# MSEBIM register map
Registers from a debugger description file.
Registers are 32-bit, access not given, no defined reset value unless marked. A register's access mark holds for its fields unless they carry their own. Addresses are absolute; registers are grouped by the start of their names; lines under a group give offsets from that group; [hi:lo] are bit positions; {n}, {i} and the like mark numbered series; 'fields as' and 'values as' point back to an identical list; <NAME> marks a mode.

## rMSEBIM
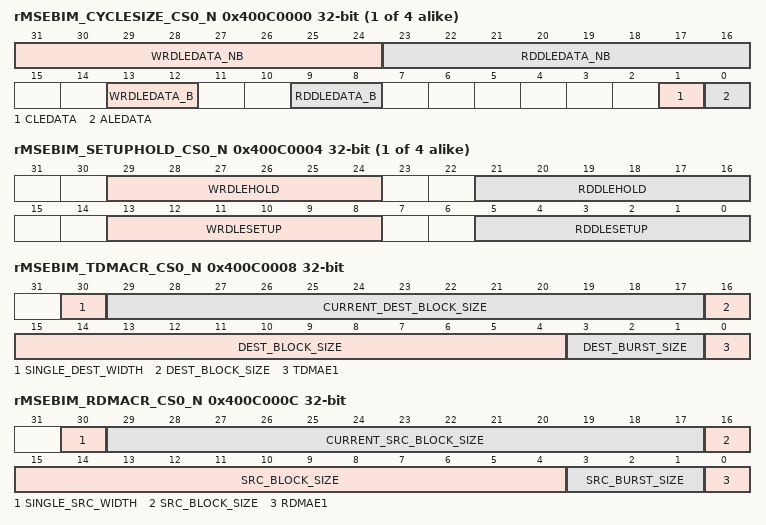
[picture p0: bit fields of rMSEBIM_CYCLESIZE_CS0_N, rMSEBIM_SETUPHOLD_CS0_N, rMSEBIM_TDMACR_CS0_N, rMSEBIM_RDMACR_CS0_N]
{0x400C0000+0x100*i} rMSEBIM_CYCLESIZE_CS{i}_N (i=0..3)
  [31:24] WRDLEDATA_NB, [23:16] RDDLEDATA_NB, [13:12] WRDLEDATA_B, [9:8] RDDLEDATA_B, [1] CLEDATA, [0] ALEDATA
{0x400C0004+0x100*i} rMSEBIM_SETUPHOLD_CS{i}_N (i=0..3)
  [29:24] WRDLEHOLD, [21:16] RDDLEHOLD, [13:8] WRDLESETUP, [5:0] RDDLESETUP
0x400C0008 rMSEBIM_TDMACR_CS0_N
  [30] SINGLE_DEST_WIDTH, [29:17] CURRENT_DEST_BLOCK_SIZE, [16:4] DEST_BLOCK_SIZE, [3:1] DEST_BURST_SIZE, [0] TDMAE1
0x400C000C rMSEBIM_RDMACR_CS0_N
  [30] SINGLE_SRC_WIDTH, [29:17] CURRENT_SRC_BLOCK_SIZE, [16:4] SRC_BLOCK_SIZE, [3:1] SRC_BURST_SIZE, [0] RDMAE1
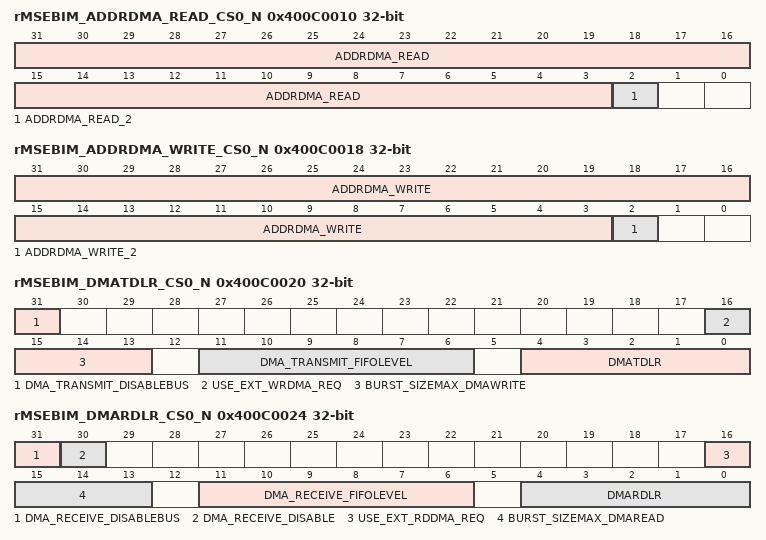
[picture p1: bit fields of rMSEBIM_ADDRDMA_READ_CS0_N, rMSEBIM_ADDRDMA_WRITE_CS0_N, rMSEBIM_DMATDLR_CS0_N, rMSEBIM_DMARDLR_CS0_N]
0x400C0010 rMSEBIM_ADDRDMA_READ_CS0_N
  [31:3] ADDRDMA_READ, [2] ADDRDMA_READ_2
0x400C0014 rMSEBIM_ADDRDMA_CURRENTREAD_CS0_N ro
  [31:0] ADDRDMA_CURRENTREAD
0x400C0018 rMSEBIM_ADDRDMA_WRITE_CS0_N
  [31:3] ADDRDMA_WRITE, [2] ADDRDMA_WRITE_2
0x400C001C rMSEBIM_ADDRDMA_CURRENTWRITE_CS0_N ro
  [31:0] ADDRDMA_CURRENTWRITE
0x400C0020 rMSEBIM_DMATDLR_CS0_N
  [31] DMA_TRANSMIT_DISABLEBUS, [16] USE_EXT_WRDMA_REQ, [15:13] BURST_SIZEMAX_DMAWRITE, [11:6] DMA_TRANSMIT_FIFOLEVEL, [4:0] DMATDLR
0x400C0024 rMSEBIM_DMARDLR_CS0_N
  [31] DMA_RECEIVE_DISABLEBUS, [30] DMA_RECEIVE_DISABLE, [16] USE_EXT_RDDMA_REQ, [15:13] BURST_SIZEMAX_DMAREAD, [11:6] DMA_RECEIVE_FIFOLEVEL, [4:0] DMARDLR
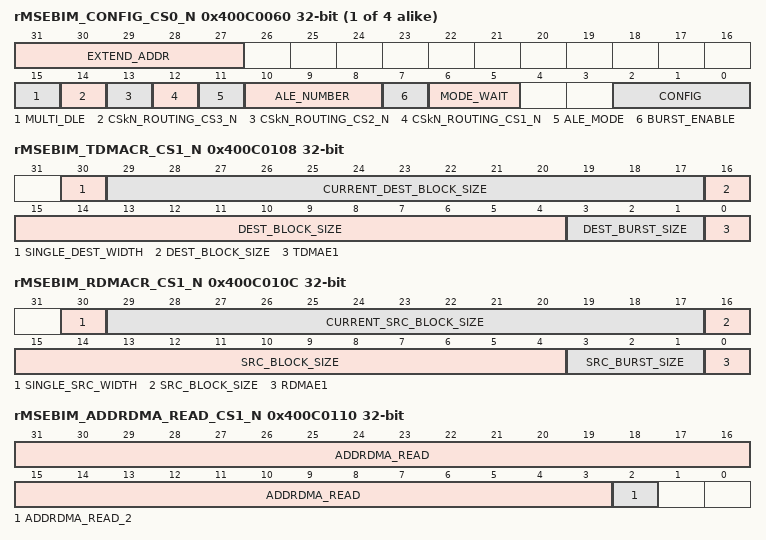
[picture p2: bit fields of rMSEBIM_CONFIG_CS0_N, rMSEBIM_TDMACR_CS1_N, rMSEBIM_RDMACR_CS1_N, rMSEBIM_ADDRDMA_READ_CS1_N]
{0x400C0060+0x100*i} rMSEBIM_CONFIG_CS{i}_N (i=0..3)
  [31:27] EXTEND_ADDR, [15] MULTI_DLE, [14] CSkN_ROUTING_CS3_N, [13] CSkN_ROUTING_CS2_N, [12] CSkN_ROUTING_CS1_N, [11] ALE_MODE, [10:8] ALE_NUMBER, [7] BURST_ENABLE, [6:5] MODE_WAIT, [2:0] CONFIG
0x400C0108 rMSEBIM_TDMACR_CS1_N
  fields as rMSEBIM_TDMACR_CS0_N
0x400C010C rMSEBIM_RDMACR_CS1_N
  fields as rMSEBIM_RDMACR_CS0_N
0x400C0110 rMSEBIM_ADDRDMA_READ_CS1_N
  [31:3] ADDRDMA_READ, [2] ADDRDMA_READ_2
0x400C0114 rMSEBIM_ADDRDMA_CURRENTREAD_CS1_N ro
  [31:0] ADDRDMA_CURRENTREAD
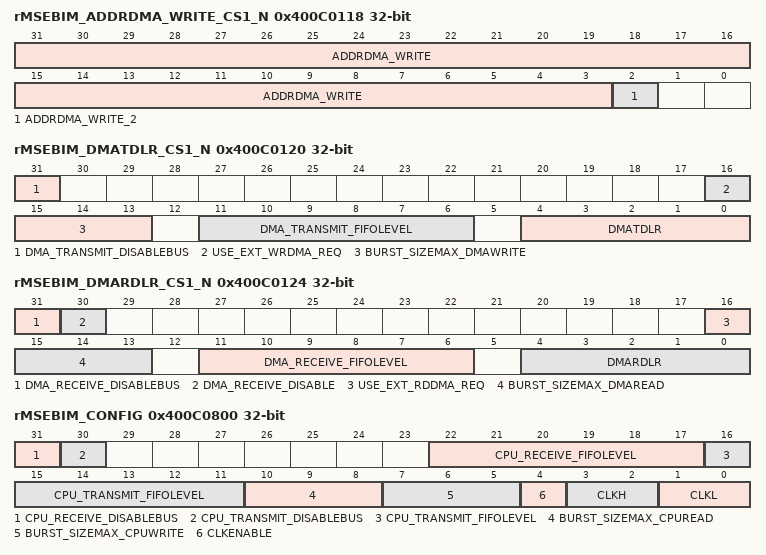
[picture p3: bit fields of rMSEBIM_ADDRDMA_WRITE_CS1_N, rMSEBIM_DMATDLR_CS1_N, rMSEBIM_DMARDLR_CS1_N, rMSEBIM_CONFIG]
0x400C0118 rMSEBIM_ADDRDMA_WRITE_CS1_N
  [31:3] ADDRDMA_WRITE, [2] ADDRDMA_WRITE_2
0x400C011C rMSEBIM_ADDRDMA_CURRENTWRITE_CS1_N ro
  [31:0] ADDRDMA_CURRENTWRITE
0x400C0120 rMSEBIM_DMATDLR_CS1_N
  fields as rMSEBIM_DMATDLR_CS0_N
0x400C0124 rMSEBIM_DMARDLR_CS1_N
  fields as rMSEBIM_DMARDLR_CS0_N
0x400C0800 rMSEBIM_CONFIG
  [31] CPU_RECEIVE_DISABLEBUS, [30] CPU_TRANSMIT_DISABLEBUS, [22:17] CPU_RECEIVE_FIFOLEVEL, [16:11] CPU_TRANSMIT_FIFOLEVEL, [10:8] BURST_SIZEMAX_CPUREAD, [7:5] BURST_SIZEMAX_CPUWRITE, [4] CLKENABLE, [3:2] CLKH, [1:0] CLKL
0x400C0808 rMSEBIM_CPU_FIFOREAD_FLUSH
  [31:0] CPU_FIFOREAD_FLUSH
